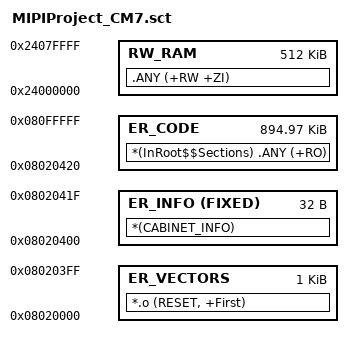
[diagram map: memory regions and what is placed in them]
LR_FLASH 0x08020000 0xE0000 {
 ER_VECTORS 0x08020000 0x400 { *.o (RESET, +First) }
 ER_INFO 0x08020400 FIXED 0x20 { *(CABINET_INFO) }
 ER_CODE 0x08020420 0xDFBE0 { *(InRoot$$Sections) .ANY (+RO) }
 RW_RAM 0x24000000 0x80000 { .ANY (+RW +ZI) }
}
